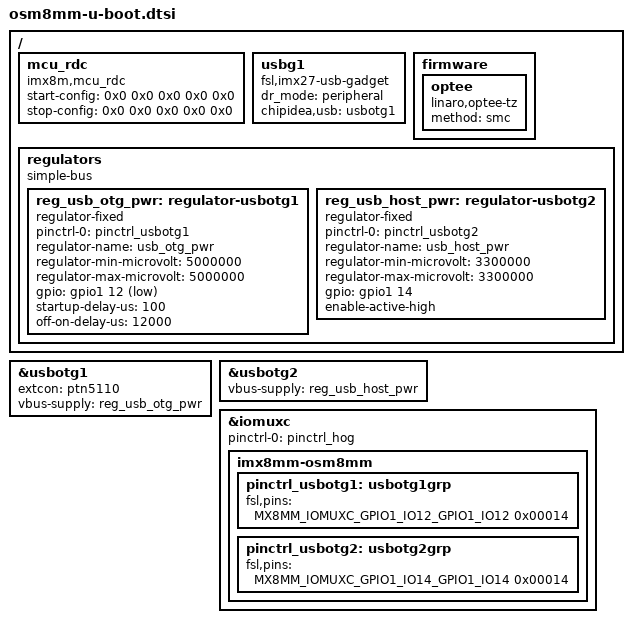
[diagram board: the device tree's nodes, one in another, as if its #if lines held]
// SPDX-License-Identifier: GPL-2.0+
/*
 * Copyright 2019 NXP
 */

/* TODO: Power polarity can't be set by DT
*  Default its low for both ports. Use regulator
*  to set pin value to correct state.
*/
/* USB0:
*  Enable regulator to activate
*  power pin for otg host devices.
*/
#define CONFIG_USB_OTG_PWR
/* USB1:
*  Enable regulator to activate power pin
*  for USB Hub.
*/
#define CONFIG_USB_HOST_PWR

/ {
	mcu_rdc {
		compatible = "imx8m,mcu_rdc";
			    /* rdc config when MCU starts
			     * master
			     *   SDMA3p --> domain 1
			     *   SDMA3b --> domain 1
			     *   SDMA3_SPBA2  --> domain 1
			     * peripheral:
			     *   SAI3   --> Only Domain 1 can access
			     *   UART4  --> Only Domain 1 can access
			     *   GPT1   --> Only Domain 1 can access
			     *   SDMA3  --> Only Domain 1 can access
			     *   I2C3   --> Only Domain 1 can access
			     * memory:
			     *   TCM    --> Only Domain 1 can access (0x7E0000~0x81FFFF)
			     *   DDR    --> Only Domain 1 can access (0x80000000~0x81000000)
			     * end.
			     */

		start-config = <
#if 0 // ### Check if these settings are correct for F&S
			    RDC_MDA  RDC_MDA_SDMA3p DID1 0x0 0x0
			    RDC_MDA  RDC_MDA_SDMA3b DID1 0x0 0x0
			    RDC_MDA  RDC_MDA_SDMA3_SPBA2 DID1 0x0 0x0
			    RDC_PDAP RDC_PDAP_SAI3  PDAP_D1_ACCESS 0x0 0x0
			    RDC_PDAP RDC_PDAP_UART4 PDAP_D1_ACCESS 0x0 0x0
			    RDC_PDAP RDC_PDAP_GPT1  PDAP_D1_ACCESS 0x0 0x0
			    RDC_PDAP RDC_PDAP_SDMA3 PDAP_D1_ACCESS 0x0 0x0
			    RDC_PDAP RDC_PDAP_I2C3  PDAP_D1_ACCESS 0x0 0x0
			    RDC_MEM_REGION 22 TCM_START TCM_END MEM_D1_ACCESS
			    RDC_MEM_REGION 39 M4_DDR_START M4_DDR_END MEM_D1_ACCESS
#endif
			    0x0      0x0            0x0  0x0 0x0
			  >;
			    /* rdc config when MCU stops
			     * memory:
			     *   TCM    --> domain 0/1 can access (0x7E0000~0x81FFFF)
			     *   DDR    --> domain 0/1 can access (0x80000000~0x81000000)
			     * end.
			     */
		stop-config = <
#if 0 // ### Check if these settings are correct for F&S
			    RDC_MEM_REGION 22 TCM_START TCM_END MEM_D0D1_ACCESS
			    RDC_MEM_REGION 39 M4_DDR_START M4_DDR_END MEM_D0D1_ACCESS
#endif
			    0x0      0x0            0x0  0x0 0x0
			  >;
	};

	usbg1: usbg1 {
		compatible = "fsl,imx27-usb-gadget";
		dr_mode = "peripheral";
		chipidea,usb = <&usbotg1>;
		status = "okay";
	};

	firmware {
		optee {
			compatible = "linaro,optee-tz";
			method = "smc";
		};
	};

	regulators {
		compatible = "simple-bus";
		#address-cells = <1>;
		#size-cells = <0>;

		#ifdef CONFIG_USB_OTG_PWR
		reg_usb_otg_pwr: regulator-usbotg1 {
			pinctrl-names = "default";
			pinctrl-0 = <&pinctrl_usbotg1>;
			compatible = "regulator-fixed";
			regulator-name = "usb_otg_pwr";
			regulator-min-microvolt = <5000000>;
			regulator-max-microvolt = <5000000>;
			gpio = <&gpio1 12 GPIO_ACTIVE_LOW>;
			startup-delay-us = <100>;
			off-on-delay-us = <12000>;
		};
		#endif
		#ifdef CONFIG_USB_HOST_PWR
		reg_usb_host_pwr: regulator-usbotg2 {
			pinctrl-names = "default";
			pinctrl-0 = <&pinctrl_usbotg2>;
			compatible = "regulator-fixed";
			regulator-name = "usb_host_pwr";
			regulator-min-microvolt = <3300000>;
			regulator-max-microvolt = <3300000>;
			gpio = <&gpio1 14 GPIO_ACTIVE_HIGH>;
			enable-active-high;
		};
		#endif
	};
};


&usbotg1 {
	#ifdef CONFIG_OSM8MM_USB_A_USBC
	extcon = <&ptn5110>;
	#endif
	#ifdef CONFIG_USB_OTG_PWR
	vbus-supply = <&reg_usb_otg_pwr>;
	#else
	pinctrl-names = "default";
	pinctrl-0 = <&pinctrl_usbotg1>;
	#endif
};

&usbotg2 {

	#ifdef CONFIG_USB_HOST_PWR
	vbus-supply = <&reg_usb_host_pwr>;
	#else
	pinctrl-names = "default";
	pinctrl-0 = <&pinctrl_usbotg2>;
	#endif
};

&iomuxc {
	pinctrl-names = "default";
	pinctrl-0 = <&pinctrl_hog>;

	imx8mm-osm8mm {

		pinctrl_usbotg1: usbotg1grp {
			fsl,pins = <
				#ifdef CONFIG_USB_OTG_PWR
				MX8MM_IOMUXC_GPIO1_IO12_GPIO1_IO12	0x00014
				#else
				MX8MM_IOMUXC_GPIO1_IO12_USB1_OTG_PWR	0x00014
				#endif
			>;
		};

		pinctrl_usbotg2: usbotg2grp {
			fsl,pins = <
				#ifdef CONFIG_USB_HOST_PWR
				MX8MM_IOMUXC_GPIO1_IO14_GPIO1_IO14	0x00014
				#else
				MX8MM_IOMUXC_GPIO1_IO14_USB2_OTG_PWR	0x00014
				#endif
			>;
		};
	};
};
